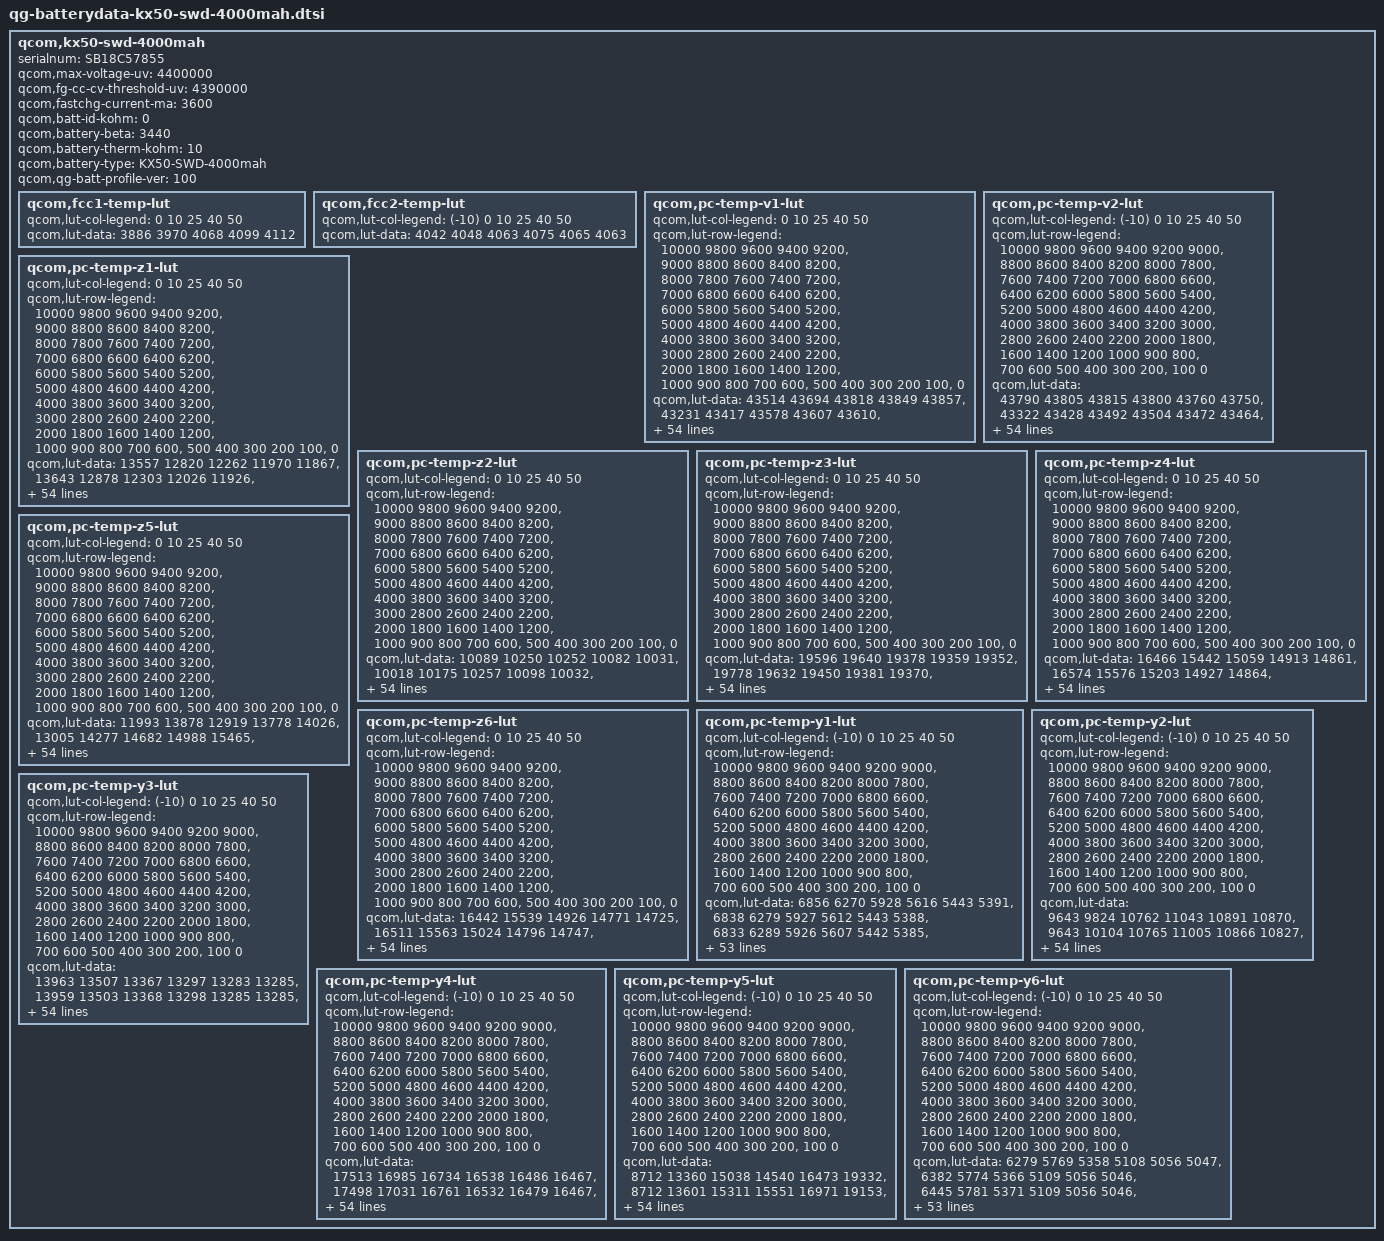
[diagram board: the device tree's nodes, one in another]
qcom,kx50-swd-4000mah {
    /* 4190768_LENOVO_Sofia_SUNWODA_4000MAH_PMI632_averaged_MasterSlave_Sep5th2019 */
    serialnum = "SB18C57855";
    qcom,max-voltage-uv = <4400000>;
    qcom,fg-cc-cv-threshold-uv = <4390000>;
    qcom,fastchg-current-ma = <3600>;
    qcom,batt-id-kohm = <0>;
    qcom,battery-beta = <3440>;
    qcom,battery-therm-kohm = <10>;
    qcom,battery-type = "KX50-SWD-4000mah";
    qcom,qg-batt-profile-ver = <100>;

	qcom,fcc1-temp-lut {
		qcom,lut-col-legend = <0 10 25 40 50>;
		qcom,lut-data = <3886 3970 4068 4099 4112>;
	};

	qcom,fcc2-temp-lut {
		qcom,lut-col-legend = <(-10) 0 10 25 40 50>;
		qcom,lut-data = <4042 4048 4063 4075 4065 4063>;
	};

	qcom,pc-temp-v1-lut {
		qcom,lut-col-legend = <0 10 25 40 50>;
		qcom,lut-row-legend = <10000 9800 9600 9400 9200>,
			<9000 8800 8600 8400 8200>,
			<8000 7800 7600 7400 7200>,
			<7000 6800 6600 6400 6200>,
			<6000 5800 5600 5400 5200>,
			<5000 4800 4600 4400 4200>,
			<4000 3800 3600 3400 3200>,
			<3000 2800 2600 2400 2200>,
			<2000 1800 1600 1400 1200>,
			<1000 900 800 700 600>,
			<500 400 300 200 100>,
			<0>;
		qcom,lut-data = <43514 43694 43818 43849 43857>,
			<43231 43417 43578 43607 43610>,
			<42978 43154 43331 43366 43376>,
			<42744 42908 43082 43125 43138>,
			<42517 42674 42837 42887 42901>,
			<42295 42443 42596 42648 42664>,
			<42080 42217 42361 42410 42429>,
			<41869 41997 42129 42175 42194>,
			<41662 41780 41902 41944 41962>,
			<41469 41567 41675 41716 41733>,
			<41309 41371 41452 41486 41505>,
			<41146 41207 41249 41265 41282>,
			<40917 41036 41080 41061 41063>,
			<40585 40790 40900 40865 40850>,
			<40279 40469 40639 40643 40642>,
			<40063 40202 40324 40392 40439>,
			<39887 40014 40100 40176 40246>,
			<39752 39862 39960 40023 40068>,
			<39644 39742 39833 39886 39899>,
			<39541 39640 39699 39736 39735>,
			<39430 39512 39554 39577 39578>,
			<39316 39329 39354 39388 39397>,
			<39193 39127 39064 39131 39151>,
			<39058 38930 38835 38895 38913>,
			<38920 38730 38718 38754 38769>,
			<38780 38596 38632 38651 38663>,
			<38638 38524 38550 38554 38561>,
			<38532 38470 38475 38463 38456>,
			<38461 38420 38406 38377 38359>,
			<38404 38377 38339 38293 38275>,
			<38363 38337 38277 38216 38200>,
			<38332 38297 38220 38152 38132>,
			<38305 38260 38168 38099 38071>,
			<38281 38225 38120 38048 38014>,
			<38260 38194 38079 37998 37960>,
			<38235 38161 38040 37948 37907>,
			<38210 38130 38002 37901 37852>,
			<38175 38094 37964 37857 37796>,
			<38121 38038 37912 37800 37727>,
			<38040 37948 37826 37714 37637>,
			<37942 37844 37722 37609 37531>,
			<37808 37730 37611 37497 37421>,
			<37673 37597 37483 37370 37297>,
			<37553 37430 37329 37216 37142>,
			<37406 37282 37185 37080 37009>,
			<37293 37189 37086 36993 36927>,
			<37255 37157 37060 36963 36901>,
			<37220 37138 37038 36945 36881>,
			<37187 37111 37022 36924 36858>,
			<37131 37059 36967 36860 36781>,
			<36896 36827 36714 36592 36488>,
			<36450 36383 36280 36153 36051>,
			<35876 35817 35714 35582 35477>,
			<35099 35037 34935 34801 34694>,
			<33874 33824 33726 33592 33478>,
			<30000 30000 30000 30000 30000>;
	};

	qcom,pc-temp-v2-lut {
		qcom,lut-col-legend = <(-10) 0 10 25 40 50>;
		qcom,lut-row-legend = <10000 9800 9600 9400 9200 9000>,
			<8800 8600 8400 8200 8000 7800>,
			<7600 7400 7200 7000 6800 6600>,
			<6400 6200 6000 5800 5600 5400>,
			<5200 5000 4800 4600 4400 4200>,
			<4000 3800 3600 3400 3200 3000>,
			<2800 2600 2400 2200 2000 1800>,
			<1600 1400 1200 1000 900 800>,
			<700 600 500 400 300 200>,
			<100 0>;
		qcom,lut-data = <43790 43805 43815 43800 43760 43750>,
			<43322 43428 43492 43504 43472 43464>,
			<42920 43086 43189 43224 43199 43193>,
			<42604 42785 42912 42963 42941 42937>,
			<42357 42517 42657 42718 42698 42696>,
			<42098 42269 42410 42479 42459 42458>,
			<41705 42047 42166 42240 42222 42221>,
			<41364 41832 41930 42005 41987 41987>,
			<41327 41569 41703 41776 41757 41756>,
			<41356 41256 41483 41551 41529 41528>,
			<41369 41080 41275 41329 41304 41303>,
			<41203 41038 41092 41111 41083 41082>,
			<40882 41003 40906 40897 40867 40866>,
			<40472 40785 40680 40694 40661 40658>,
			<39893 40207 40419 40496 40462 40455>,
			<39506 39798 40167 40283 40267 40260>,
			<39341 39631 39922 40034 40073 40072>,
			<39208 39495 39697 39809 39888 39892>,
			<39023 39320 39519 39662 39720 39724>,
			<38808 39126 39366 39544 39563 39563>,
			<38622 38938 39194 39382 39379 39378>,
			<38464 38757 38992 39143 39148 39149>,
			<38338 38583 38800 38912 38925 38928>,
			<38259 38406 38643 38739 38749 38751>,
			<38200 38236 38503 38592 38597 38598>,
			<38147 38133 38379 38467 38470 38470>,
			<38096 38077 38268 38360 38362 38361>,
			<38048 38032 38166 38264 38265 38262>,
			<38001 37987 38062 38174 38176 38171>,
			<37954 37946 37968 38092 38096 38088>,
			<37905 37905 37909 38018 38024 38015>,
			<37853 37866 37871 37950 37958 37949>,
			<37800 37825 37837 37888 37895 37885>,
			<37746 37780 37805 37829 37834 37822>,
			<37693 37730 37774 37775 37771 37755>,
			<37635 37677 37735 37721 37696 37669>,
			<37572 37618 37691 37668 37605 37559>,
			<37504 37555 37638 37607 37518 37455>,
			<37429 37486 37574 37536 37441 37372>,
			<37348 37411 37495 37458 37366 37295>,
			<37266 37332 37395 37377 37289 37218>,
			<37183 37248 37270 37285 37205 37136>,
			<37103 37160 37155 37169 37095 37029>,
			<37028 37067 37055 37038 36962 36897>,
			<36951 36946 36957 36920 36847 36784>,
			<36865 36812 36862 36863 36806 36751>,
			<36809 36755 36808 36845 36792 36739>,
			<36745 36704 36756 36823 36775 36720>,
			<36668 36654 36687 36783 36743 36687>,
			<36552 36572 36586 36690 36640 36564>,
			<36322 36393 36379 36410 36306 36198>,
			<35914 35998 35995 35907 35812 35695>,
			<35317 35391 35408 35271 35166 35039>,
			<34430 34543 34589 34395 34295 34141>,
			<33023 33155 33314 33121 32966 32787>,
			<28247 27971 28433 28065 28352 28266>;
	};

	qcom,pc-temp-z1-lut {
		qcom,lut-col-legend = <0 10 25 40 50>;
		qcom,lut-row-legend = <10000 9800 9600 9400 9200>,
			<9000 8800 8600 8400 8200>,
			<8000 7800 7600 7400 7200>,
			<7000 6800 6600 6400 6200>,
			<6000 5800 5600 5400 5200>,
			<5000 4800 4600 4400 4200>,
			<4000 3800 3600 3400 3200>,
			<3000 2800 2600 2400 2200>,
			<2000 1800 1600 1400 1200>,
			<1000 900 800 700 600>,
			<500 400 300 200 100>,
			<0>;
		qcom,lut-data = <13557 12820 12262 11970 11867>,
			<13643 12878 12303 12026 11926>,
			<13669 12908 12309 12028 11934>,
			<13684 12911 12309 12026 11937>,
			<13684 12903 12305 12024 11937>,
			<13661 12891 12298 12020 11937>,
			<13643 12868 12293 12017 11937>,
			<13644 12855 12287 12015 11938>,
			<13650 12858 12280 12014 11940>,
			<13647 12863 12279 12014 11942>,
			<13622 12862 12281 12015 11941>,
			<13585 12861 12281 12017 11941>,
			<13556 12859 12277 12017 11940>,
			<13521 12848 12270 12017 11940>,
			<13492 12816 12257 12012 11940>,
			<13470 12795 12241 12003 11940>,
			<13451 12789 12238 11998 11939>,
			<13453 12787 12243 12001 11939>,
			<13461 12793 12250 12005 11940>,
			<13469 12806 12256 12008 11941>,
			<13473 12819 12263 12010 11943>,
			<13472 12833 12269 12012 11944>,
			<13470 12845 12275 12013 11945>,
			<13466 12847 12278 12015 11945>,
			<13466 12845 12281 12017 11947>,
			<13472 12845 12284 12020 11950>,
			<13483 12854 12286 12024 11953>,
			<13495 12864 12288 12028 11957>,
			<13514 12862 12291 12032 11961>,
			<13536 12852 12297 12036 11965>,
			<13549 12849 12305 12040 11969>,
			<13557 12866 12308 12045 11973>,
			<13562 12890 12309 12049 11977>,
			<13556 12896 12310 12054 11981>,
			<13546 12897 12316 12059 11984>,
			<13548 12896 12323 12064 11987>,
			<13558 12897 12328 12069 11991>,
			<13569 12900 12332 12074 11994>,
			<13590 12907 12336 12078 11997>,
			<13618 12924 12342 12083 12000>,
			<13624 12933 12348 12087 12004>,
			<13604 12932 12357 12090 12008>,
			<13596 12933 12368 12094 12011>,
			<13615 12942 12370 12098 12014>,
			<13647 12958 12377 12103 12017>,
			<13648 12956 12388 12106 12018>,
			<13644 12969 12388 12107 12019>,
			<13611 12943 12391 12108 12020>,
			<13626 12974 12389 12112 12023>,
			<13650 12957 12399 12119 12026>,
			<13677 12967 12411 12122 12033>,
			<13723 12997 12419 12131 12041>,
			<13697 13033 12439 12145 12052>,
			<13739 13090 12451 12166 12068>,
			<13739 13090 12451 12166 12068>,
			<13739 13090 12451 12166 12068>;
	};

	qcom,pc-temp-z2-lut {
		qcom,lut-col-legend = <0 10 25 40 50>;
		qcom,lut-row-legend = <10000 9800 9600 9400 9200>,
			<9000 8800 8600 8400 8200>,
			<8000 7800 7600 7400 7200>,
			<7000 6800 6600 6400 6200>,
			<6000 5800 5600 5400 5200>,
			<5000 4800 4600 4400 4200>,
			<4000 3800 3600 3400 3200>,
			<3000 2800 2600 2400 2200>,
			<2000 1800 1600 1400 1200>,
			<1000 900 800 700 600>,
			<500 400 300 200 100>,
			<0>;
		qcom,lut-data = <10089 10250 10252 10082 10031>,
			<10018 10175 10257 10098 10032>,
			<10052 10174 10261 10179 10034>,
			<10065 10176 10257 10205 10095>,
			<10072 10154 10242 10201 10121>,
			<10083 10128 10214 10185 10071>,
			<10093 10106 10233 10169 10031>,
			<10093 10089 10432 10146 10020>,
			<10083 10076 10564 10102 9995>,
			<10075 10067 10415 10082 9971>,
			<10109 10064 10188 10089 9951>,
			<10176 10065 10149 10100 9938>,
			<10176 10068 10155 10088 9945>,
			<10067 10078 10165 10057 9959>,
			<9976 10099 10185 10066 9973>,
			<9968 10112 10211 10141 9985>,
			<9966 10115 10212 10181 9997>,
			<9968 10118 10179 10112 10006>,
			<9980 10128 10155 10033 10017>,
			<9994 10151 10178 10033 10032>,
			<10003 10179 10232 10066 10056>,
			<10010 10222 10288 10103 10080>,
			<10020 10257 10352 10151 10103>,
			<10037 10255 10380 10184 10123>,
			<10056 10241 10321 10174 10136>,
			<10070 10237 10239 10145 10146>,
			<10083 10244 10237 10141 10176>,
			<10094 10251 10276 10170 10328>,
			<10103 10253 10309 10206 10455>,
			<10110 10257 10329 10264 10385>,
			<10117 10262 10346 10346 10218>,
			<10123 10267 10355 10347 10108>,
			<10128 10273 10362 10249 10027>,
			<10132 10280 10365 10186 9988>,
			<10135 10289 10362 10185 10001>,
			<10141 10299 10359 10185 10027>,
			<10151 10308 10363 10184 10058>,
			<10164 10316 10371 10182 10104>,
			<10177 10328 10385 10185 10147>,
			<10193 10346 10419 10218 10185>,
			<10208 10357 10446 10267 10210>,
			<10227 10358 10445 10312 10206>,
			<10219 10360 10439 10347 10192>,
			<9980 10374 10436 10335 10198>,
			<10499 10475 10453 10309 10210>,
			<10708 10528 10475 10277 10184>,
			<10816 10524 10462 10257 10182>,
			<11020 10548 10458 10267 10195>,
			<11529 10556 10438 10288 10209>,
			<12272 10660 10467 10372 10267>,
			<11377 15617 10516 10307 10135>,
			<10316 10759 10445 10173 10023>,
			<10200 15315 10418 10118 9974>,
			<10044 10544 10355 10058 9925>,
			<10044 10544 10355 10058 9925>,
			<10044 10544 10355 10058 9925>;
	};

	qcom,pc-temp-z3-lut {
		qcom,lut-col-legend = <0 10 25 40 50>;
		qcom,lut-row-legend = <10000 9800 9600 9400 9200>,
			<9000 8800 8600 8400 8200>,
			<8000 7800 7600 7400 7200>,
			<7000 6800 6600 6400 6200>,
			<6000 5800 5600 5400 5200>,
			<5000 4800 4600 4400 4200>,
			<4000 3800 3600 3400 3200>,
			<3000 2800 2600 2400 2200>,
			<2000 1800 1600 1400 1200>,
			<1000 900 800 700 600>,
			<500 400 300 200 100>,
			<0>;
		qcom,lut-data = <19596 19640 19378 19359 19352>,
			<19778 19632 19450 19381 19370>,
			<19827 19643 19479 19415 19392>,
			<19847 19655 19494 19429 19408>,
			<19851 19661 19497 19433 19414>,
			<19844 19663 19498 19438 19417>,
			<19829 19661 19502 19441 19419>,
			<19813 19657 19516 19440 19420>,
			<19794 19654 19526 19436 19418>,
			<19782 19650 19516 19432 19415>,
			<19787 19645 19498 19427 19410>,
			<19805 19627 19484 19424 19405>,
			<19821 19608 19468 19418 19401>,
			<19840 19605 19455 19411 19399>,
			<19848 19609 19458 19410 19396>,
			<19834 19609 19469 19416 19394>,
			<19804 19598 19471 19419 19391>,
			<19778 19582 19454 19405 19385>,
			<19752 19568 19438 19386 19379>,
			<19734 19555 19432 19380 19373>,
			<19728 19551 19429 19378 19368>,
			<19725 19561 19432 19378 19366>,
			<19725 19571 19448 19382 19367>,
			<19732 19573 19458 19385 19367>,
			<19740 19574 19447 19378 19362>,
			<19743 19574 19430 19363 19348>,
			<19745 19570 19426 19359 19346>,
			<19746 19565 19425 19367 19387>,
			<19742 19562 19425 19379 19423>,
			<19735 19558 19431 19398 19422>,
			<19729 19556 19441 19421 19416>,
			<19721 19556 19448 19424 19410>,
			<19712 19555 19455 19416 19402>,
			<19704 19555 19457 19408 19394>,
			<19696 19554 19454 19402 19384>,
			<19688 19552 19450 19396 19374>,
			<19679 19548 19444 19389 19369>,
			<19671 19542 19436 19381 19366>,
			<19663 19537 19430 19376 19363>,
			<19656 19532 19428 19373 19361>,
			<19649 19527 19425 19371 19359>,
			<19644 19521 19423 19373 19360>,
			<19612 19514 19420 19376 19362>,
			<19308 19508 19414 19376 19368>,
			<19260 19485 19403 19371 19367>,
			<19259 19458 19396 19357 19355>,
			<19259 19456 19390 19357 19345>,
			<19259 19438 19389 19349 19340>,
			<19258 19436 19376 19344 19334>,
			<19257 19432 19368 19339 19336>,
			<19259 19346 19371 19351 19366>,
			<19261 19414 19387 19368 19366>,
			<19261 19341 19365 19371 19367>,
			<19262 19358 19363 19369 19368>,
			<19262 19358 19363 19369 19368>,
			<19262 19358 19363 19369 19368>;
	};

	qcom,pc-temp-z4-lut {
		qcom,lut-col-legend = <0 10 25 40 50>;
		qcom,lut-row-legend = <10000 9800 9600 9400 9200>,
			<9000 8800 8600 8400 8200>,
			<8000 7800 7600 7400 7200>,
			<7000 6800 6600 6400 6200>,
			<6000 5800 5600 5400 5200>,
			<5000 4800 4600 4400 4200>,
			<4000 3800 3600 3400 3200>,
			<3000 2800 2600 2400 2200>,
			<2000 1800 1600 1400 1200>,
			<1000 900 800 700 600>,
			<500 400 300 200 100>,
			<0>;
		qcom,lut-data = <16466 15442 15059 14913 14861>,
			<16574 15576 15203 14927 14864>,
			<16401 15580 15158 14953 14892>,
			<16088 15451 15063 14914 14872>,
			<15844 15277 14996 14876 14847>,
			<15675 15156 14942 14843 14824>,
			<15538 15070 14887 14815 14801>,
			<15433 15002 14823 14791 14780>,
			<15353 14951 14784 14772 14760>,
			<15272 14911 14777 14757 14746>,
			<15156 14875 14777 14744 14737>,
			<15036 14834 14769 14734 14730>,
			<14989 14804 14752 14725 14723>,
			<14978 14799 14741 14717 14716>,
			<14974 14804 14747 14717 14711>,
			<14961 14807 14762 14725 14706>,
			<14935 14798 14765 14729 14702>,
			<14904 14782 14738 14713 14695>,
			<14868 14760 14713 14694 14689>,
			<14835 14734 14707 14690 14688>,
			<14810 14726 14705 14689 14688>,
			<14790 14747 14721 14696 14692>,
			<14784 14782 14811 14768 14757>,
			<14786 14829 14873 14841 14831>,
			<14790 14892 14880 14851 14839>,
			<14807 14918 14883 14855 14840>,
			<14844 14906 14880 14853 14835>,
			<14862 14887 14863 14830 14779>,
			<14862 14869 14842 14801 14724>,
			<14859 14851 14821 14767 14712>,
			<14853 14833 14799 14733 14706>,
			<14840 14818 14779 14718 14701>,
			<14826 14804 14762 14711 14696>,
			<14813 14792 14752 14708 14694>,
			<14801 14782 14746 14708 14694>,
			<14789 14773 14743 14709 14695>,
			<14777 14764 14742 14709 14696>,
			<14767 14758 14740 14711 14697>,
			<14758 14757 14740 14713 14699>,
			<14751 14758 14746 14723 14711>,
			<14747 14759 14751 14732 14724>,
			<14743 14749 14745 14727 14720>,
			<14762 14736 14733 14715 14710>,
			<15050 14728 14728 14715 14709>,
			<15017 14703 14712 14709 14703>,
			<14982 14685 14685 14686 14680>,
			<14975 14678 14677 14678 14678>,
			<14968 14681 14663 14667 14665>,
			<14961 14673 14659 14648 14643>,
			<14950 14669 14660 14647 14634>,
			<14956 14775 14684 14674 14656>,
			<14975 14714 14678 14668 14667>,
			<14987 14797 14704 14669 14670>,
			<15003 14791 14708 14673 14671>,
			<15003 14791 14708 14673 14671>,
			<15003 14791 14708 14673 14671>;
	};

	qcom,pc-temp-z5-lut {
		qcom,lut-col-legend = <0 10 25 40 50>;
		qcom,lut-row-legend = <10000 9800 9600 9400 9200>,
			<9000 8800 8600 8400 8200>,
			<8000 7800 7600 7400 7200>,
			<7000 6800 6600 6400 6200>,
			<6000 5800 5600 5400 5200>,
			<5000 4800 4600 4400 4200>,
			<4000 3800 3600 3400 3200>,
			<3000 2800 2600 2400 2200>,
			<2000 1800 1600 1400 1200>,
			<1000 900 800 700 600>,
			<500 400 300 200 100>,
			<0>;
		qcom,lut-data = <11993 13878 12919 13778 14026>,
			<13005 14277 14682 14988 15465>,
			<13492 14741 15293 16581 16712>,
			<13804 15307 16013 17467 18067>,
			<14090 15923 16516 17906 18896>,
			<14364 16497 16865 18608 19495>,
			<14608 17094 17628 19338 20060>,
			<14815 17753 19726 19629 20662>,
			<14994 18654 21233 19796 21366>,
			<15232 19782 21006 20025 21835>,
			<15788 20486 20483 20715 22023>,
			<16778 20689 20499 21448 22182>,
			<18310 20959 20129 21579 22611>,
			<20595 22506 19653 21540 23422>,
			<21690 25884 21200 23156 24473>,
			<21194 27221 24442 27879 25894>,
			<20344 25490 25075 30039 26646>,
			<20124 23832 23111 26321 26547>,
			<20248 24073 21814 22185 26394>,
			<20494 25632 22952 22345 26495>,
			<21431 28517 25832 24345 27082>,
			<23652 37364 29915 25516 27369>,
			<26843 45677 36839 25814 26014>,
			<32751 45678 40623 25966 23587>,
			<38800 43089 34667 23611 20442>,
			<42905 40376 25263 18350 16545>,
			<46644 37012 22029 16692 15683>,
			<48116 33730 20659 16771 19972>,
			<46828 31952 20203 17011 24433>,
			<44671 30672 20924 20079 25848>,
			<42750 30214 22385 25234 26701>,
			<40702 30869 24548 26856 27369>,
			<38898 32096 27936 27244 27973>,
			<37460 33677 30595 27673 28292>,
			<36244 35906 32694 29003 27885>,
			<35380 37335 34071 30366 27079>,
			<34658 37991 33739 30066 26950>,
			<34272 38397 32329 28115 27177>,
			<34669 38368 31042 26188 27056>,
			<35524 37928 30014 24328 24972>,
			<35812 37227 28991 23037 22603>,
			<35734 35150 27916 23065 22043>,
			<34160 33431 26791 23305 21815>,
			<14051 33450 25330 23369 23530>,
			<11407 34145 25471 22939 24313>,
			<11437 30199 27162 20877 21355>,
			<11371 29900 25817 21275 18792>,
			<11353 23467 27185 20462 19019>,
			<11333 23637 23389 22529 21815>,
			<11328 24154 21713 21527 24303>,
			<11416 16686 19293 18617 25249>,
			<11372 17731 20216 19839 20826>,
			<11284 14413 15860 19056 19107>,
			<11182 13117 15086 17437 17355>,
			<11182 13117 15086 17437 17355>,
			<11182 13117 15086 17437 17355>;
	};

	qcom,pc-temp-z6-lut {
		qcom,lut-col-legend = <0 10 25 40 50>;
		qcom,lut-row-legend = <10000 9800 9600 9400 9200>,
			<9000 8800 8600 8400 8200>,
			<8000 7800 7600 7400 7200>,
			<7000 6800 6600 6400 6200>,
			<6000 5800 5600 5400 5200>,
			<5000 4800 4600 4400 4200>,
			<4000 3800 3600 3400 3200>,
			<3000 2800 2600 2400 2200>,
			<2000 1800 1600 1400 1200>,
			<1000 900 800 700 600>,
			<500 400 300 200 100>,
			<0>;
		qcom,lut-data = <16442 15539 14926 14771 14725>,
			<16511 15563 15024 14796 14747>,
			<16441 15552 15013 14821 14769>,
			<16268 15493 14982 14814 14770>,
			<16119 15400 14953 14805 14767>,
			<16010 15328 14926 14792 14759>,
			<15917 15275 14903 14780 14750>,
			<15840 15232 14884 14770 14742>,
			<15776 15199 14867 14759 14733>,
			<15718 15172 14855 14750 14726>,
			<15658 15145 14845 14742 14719>,
			<15603 15110 14834 14736 14713>,
			<15568 15080 14817 14728 14707>,
			<15545 15068 14804 14721 14703>,
			<15523 15062 14806 14720 14698>,
			<15494 15057 14814 14724 14695>,
			<15461 15047 14815 14726 14691>,
			<15429 15032 14795 14712 14685>,
			<15397 15017 14777 14694 14679>,
			<15375 15004 14774 14690 14675>,
			<15366 15000 14772 14688 14672>,
			<15360 15015 14781 14691 14672>,
			<15360 15038 14829 14725 14701>,
			<15367 15063 14861 14758 14733>,
			<15378 15091 14859 14758 14734>,
			<15392 15103 14854 14754 14729>,
			<15411 15098 14849 14750 14725>,
			<15420 15089 14842 14745 14723>,
			<15419 15082 14837 14741 14720>,
			<15417 15074 14833 14738 14717>,
			<15414 15067 14829 14736 14711>,
			<15407 15062 14826 14732 14706>,
			<15399 15058 14823 14726 14701>,
			<15393 15054 14820 14720 14695>,
			<15387 15052 14818 14718 14691>,
			<15382 15049 14815 14716 14686>,
			<15376 15046 14812 14713 14684>,
			<15373 15044 14809 14709 14682>,
			<15374 15044 14808 14707 14681>,
			<15375 15047 14811 14710 14686>,
			<15377 15049 14813 14714 14690>,
			<15381 15046 14811 14713 14689>,
			<15382 15042 14806 14711 14687>,
			<15371 15042 14803 14711 14689>,
			<15347 15031 14794 14707 14687>,
			<15338 15015 14781 14690 14671>,
			<15335 15011 14775 14687 14665>,
			<15333 15004 14769 14678 14656>,
			<15332 15002 14760 14667 14644>,
			<15335 15003 14760 14665 14642>,
			<15348 15012 14774 14685 14668>,
			<15367 15027 14784 14694 14677>,
			<15387 15038 14789 14699 14681>,
			<15420 15058 14797 14704 14686>,
			<15420 15058 14797 14704 14686>,
			<15420 15058 14797 14704 14686>;
	};

	qcom,pc-temp-y1-lut {
		qcom,lut-col-legend = <(-10) 0 10 25 40 50>;
		qcom,lut-row-legend = <10000 9800 9600 9400 9200 9000>,
			<8800 8600 8400 8200 8000 7800>,
			<7600 7400 7200 7000 6800 6600>,
			<6400 6200 6000 5800 5600 5400>,
			<5200 5000 4800 4600 4400 4200>,
			<4000 3800 3600 3400 3200 3000>,
			<2800 2600 2400 2200 2000 1800>,
			<1600 1400 1200 1000 900 800>,
			<700 600 500 400 300 200>,
			<100 0>;
		qcom,lut-data = <6856 6270 5928 5616 5443 5391>,
			<6838 6279 5927 5612 5443 5388>,
			<6833 6289 5926 5607 5442 5385>,
			<6835 6299 5925 5602 5440 5382>,
			<6839 6306 5924 5597 5439 5380>,
			<6841 6309 5923 5595 5436 5378>,
			<6847 6307 5923 5593 5434 5376>,
			<6855 6305 5923 5591 5431 5375>,
			<6856 6305 5922 5590 5429 5374>,
			<6856 6306 5921 5588 5427 5373>,
			<6856 6306 5920 5586 5426 5372>,
			<6855 6303 5917 5583 5424 5371>,
			<6854 6301 5915 5579 5423 5369>,
			<6856 6307 5916 5577 5421 5369>,
			<6862 6322 5920 5575 5416 5369>,
			<6866 6329 5924 5574 5415 5369>,
			<6861 6330 5928 5578 5420 5369>,
			<6853 6329 5931 5582 5425 5370>,
			<6850 6327 5932 5582 5424 5370>,
			<6846 6320 5933 5581 5421 5370>,
			<6844 6316 5933 5581 5420 5370>,
			<6843 6315 5929 5583 5421 5370>,
			<6842 6315 5926 5585 5422 5371>,
			<6844 6316 5927 5587 5424 5372>,
			<6851 6323 5931 5590 5426 5373>,
			<6853 6325 5934 5592 5428 5375>,
			<6844 6318 5938 5596 5431 5377>,
			<6833 6309 5940 5600 5433 5378>,
			<6836 6314 5939 5603 5436 5381>,
			<6855 6331 5936 5606 5439 5384>,
			<6863 6339 5936 5609 5442 5386>,
			<6856 6328 5946 5612 5446 5389>,
			<6848 6316 5954 5615 5449 5391>,
			<6850 6318 5950 5618 5452 5394>,
			<6858 6324 5941 5622 5455 5396>,
			<6861 6328 5939 5625 5457 5398>,
			<6847 6328 5945 5628 5459 5400>,
			<6831 6329 5949 5629 5461 5402>,
			<6830 6328 5949 5630 5463 5403>,
			<6829 6327 5949 5632 5464 5405>,
			<6830 6324 5951 5633 5466 5406>,
			<6843 6320 5957 5635 5468 5407>,
			<6855 6320 5958 5638 5470 5408>,
			<6862 6324 5953 5643 5473 5410>,
			<6863 6340 5956 5650 5478 5414>,
			<6879 6365 5974 5656 5483 5416>,
			<6869 6368 5971 5662 5484 5417>,
			<6858 6372 5966 5661 5482 5416>,
			<6861 6372 5980 5659 5482 5416>,
			<6893 6377 5984 5661 5480 5418>,
			<6941 6390 5990 5666 5486 5421>,
			<6937 6391 5990 5677 5494 5427>,
			<6941 6418 6007 5693 5505 5436>,
			<7000 6458 6041 5719 5522 5447>,
			<7000 6458 6041 5719 5522 5447>,
			<7000 6458 6041 5719 5522 5447>;
	};

	qcom,pc-temp-y2-lut {
		qcom,lut-col-legend = <(-10) 0 10 25 40 50>;
		qcom,lut-row-legend = <10000 9800 9600 9400 9200 9000>,
			<8800 8600 8400 8200 8000 7800>,
			<7600 7400 7200 7000 6800 6600>,
			<6400 6200 6000 5800 5600 5400>,
			<5200 5000 4800 4600 4400 4200>,
			<4000 3800 3600 3400 3200 3000>,
			<2800 2600 2400 2200 2000 1800>,
			<1600 1400 1200 1000 900 800>,
			<700 600 500 400 300 200>,
			<100 0>;
		qcom,lut-data = <9643 9824 10762 11043 10891 10870>,
			<9643 10104 10765 11005 10866 10827>,
			<9643 10291 10765 10969 10840 10785>,
			<9822 10402 10762 10935 10814 10747>,
			<10006 10456 10756 10905 10787 10713>,
			<10062 10468 10749 10880 10760 10687>,
			<9910 10387 10739 10857 10725 10668>,
			<9701 10278 10725 10838 10697 10652>,
			<9671 10344 10703 10827 10693 10637>,
			<9673 10654 10666 10820 10695 10623>,
			<9674 10804 10651 10815 10695 10613>,
			<9676 10589 10704 10803 10685 10608>,
			<9677 10338 10788 10792 10674 10605>,
			<9675 10387 10864 10796 10679 10602>,
			<9670 10613 10943 10816 10706 10602>,
			<9667 10739 10969 10846 10734 10602>,
			<9667 10782 10967 10916 10769 10605>,
			<9667 10811 10965 10998 10811 10612>,
			<9667 10827 10979 11067 10874 10669>,
			<9666 10839 11007 11127 10954 10800>,
			<9665 10839 11014 11139 10980 10848>,
			<9664 10778 10996 11108 10955 10834>,
			<9664 10659 10979 11082 10926 10820>,
			<9663 10358 10989 11087 10926 10828>,
			<9662 9867 11011 11101 10944 10847>,
			<9662 9700 11015 11115 10963 10869>,
			<9661 9695 10993 11135 10981 10898>,
			<9661 9691 10976 11157 11000 10924>,
			<9660 9686 10987 11179 11024 10940>,
			<9660 9681 11008 11199 11055 10954>,
			<9660 9677 11009 11214 11078 10981>,
			<9659 9673 10982 11227 11094 11027>,
			<9659 9669 10947 11231 11113 11048>,
			<9659 9667 10912 11231 11149 11047>,
			<9659 9665 10872 11230 11183 11045>,
			<9659 9663 10829 11220 11174 11032>,
			<9658 9662 10781 11184 11114 10999>,
			<9658 9660 10726 11146 11064 10977>,
			<9658 9659 10673 11114 11036 10961>,
			<9658 9659 10599 11085 11020 10941>,
			<9658 9658 10359 11063 11035 10916>,
			<9658 9658 9915 11041 11057 10894>,
			<9658 9658 9753 11007 11030 10901>,
			<9658 9657 9711 10950 10969 10899>,
			<9657 9657 9716 10929 10921 10799>,
			<9657 9658 9739 10901 10856 10733>,
			<9657 9658 9731 10880 10821 10684>,
			<9657 9657 9729 10873 10875 10668>,
			<9657 9657 9735 10888 10931 10756>,
			<9656 9657 9752 10890 10916 10735>,
			<9656 9657 9743 10841 10838 10671>,
			<9656 9656 9714 10750 10753 10594>,
			<9655 9656 9684 10675 10672 10513>,
			<9654 9655 9668 10610 10637 10429>,
			<9654 9655 9668 10610 10637 10429>,
			<9654 9655 9668 10610 10637 10429>;
	};

	qcom,pc-temp-y3-lut {
		qcom,lut-col-legend = <(-10) 0 10 25 40 50>;
		qcom,lut-row-legend = <10000 9800 9600 9400 9200 9000>,
			<8800 8600 8400 8200 8000 7800>,
			<7600 7400 7200 7000 6800 6600>,
			<6400 6200 6000 5800 5600 5400>,
			<5200 5000 4800 4600 4400 4200>,
			<4000 3800 3600 3400 3200 3000>,
			<2800 2600 2400 2200 2000 1800>,
			<1600 1400 1200 1000 900 800>,
			<700 600 500 400 300 200>,
			<100 0>;
		qcom,lut-data = <13963 13507 13367 13297 13283 13285>,
			<13959 13503 13368 13298 13285 13285>,
			<13939 13503 13371 13301 13286 13284>,
			<13906 13507 13373 13303 13287 13284>,
			<13863 13514 13376 13305 13288 13285>,
			<13813 13521 13378 13306 13289 13285>,
			<13736 13535 13381 13306 13290 13286>,
			<13665 13548 13384 13306 13290 13287>,
			<13650 13532 13387 13307 13290 13288>,
			<13645 13458 13389 13309 13291 13289>,
			<13644 13419 13391 13310 13292 13289>,
			<13656 13424 13390 13310 13292 13289>,
			<13672 13432 13389 13311 13293 13289>,
			<13654 13436 13383 13314 13294 13290>,
			<13589 13441 13371 13319 13297 13290>,
			<13559 13441 13364 13320 13298 13290>,
			<13572 13431 13361 13315 13299 13291>,
			<13588 13416 13359 13311 13300 13291>,
			<13589 13406 13355 13312 13300 13293>,
			<13586 13394 13351 13313 13300 13295>,
			<13583 13385 13347 13312 13299 13295>,
			<13579 13377 13341 13307 13294 13290>,
			<13575 13369 13336 13301 13290 13285>,
			<13585 13351 13333 13298 13287 13283>,
			<13619 13327 13330 13296 13285 13282>,
			<13652 13321 13328 13296 13284 13282>,
			<13683 13339 13325 13295 13283 13282>,
			<13716 13363 13323 13295 13283 13282>,
			<13754 13378 13319 13295 13283 13281>,
			<13797 13391 13316 13294 13283 13280>,
			<13841 13408 13315 13294 13283 13280>,
			<13888 13431 13319 13294 13283 13280>,
			<13937 13458 13323 13294 13283 13280>,
			<13987 13493 13327 13294 13283 13281>,
			<14038 13538 13331 13294 13284 13282>,
			<14087 13589 13335 13295 13284 13281>,
			<14133 13650 13339 13295 13283 13280>,
			<14178 13715 13343 13295 13282 13279>,
			<14221 13785 13348 13295 13282 13280>,
			<14261 13858 13354 13296 13283 13281>,
			<14299 13927 13360 13297 13284 13283>,
			<14333 13992 13369 13301 13287 13285>,
			<14373 14052 13387 13302 13287 13285>,
			<14425 14101 13415 13303 13284 13283>,
			<14470 14062 13428 13301 13284 13280>,
			<14475 13997 13424 13304 13289 13288>,
			<14537 14048 13439 13309 13292 13291>,
			<14608 14090 13456 13315 13296 13293>,
			<14686 14125 13469 13322 13301 13295>,
			<14771 14146 13479 13326 13299 13294>,
			<14861 14187 13486 13324 13295 13289>,
			<14994 14275 13506 13323 13297 13291>,
			<15200 14496 13561 13335 13302 13297>,
			<15707 14794 13718 13352 13312 13306>,
			<15707 14794 13718 13352 13312 13306>,
			<15707 14794 13718 13352 13312 13306>;
	};

	qcom,pc-temp-y4-lut {
		qcom,lut-col-legend = <(-10) 0 10 25 40 50>;
		qcom,lut-row-legend = <10000 9800 9600 9400 9200 9000>,
			<8800 8600 8400 8200 8000 7800>,
			<7600 7400 7200 7000 6800 6600>,
			<6400 6200 6000 5800 5600 5400>,
			<5200 5000 4800 4600 4400 4200>,
			<4000 3800 3600 3400 3200 3000>,
			<2800 2600 2400 2200 2000 1800>,
			<1600 1400 1200 1000 900 800>,
			<700 600 500 400 300 200>,
			<100 0>;
		qcom,lut-data = <17513 16985 16734 16538 16486 16467>,
			<17498 17031 16761 16532 16479 16467>,
			<17491 17086 16793 16528 16475 16467>,
			<17492 17140 16823 16525 16473 16467>,
			<17498 17185 16846 16524 16472 16467>,
			<17510 17211 16853 16524 16472 16467>,
			<17601 17221 16848 16525 16473 16466>,
			<17772 17229 16841 16528 16476 16466>,
			<17989 17260 16840 16531 16478 16466>,
			<18298 17353 16840 16535 16481 16469>,
			<18436 17478 16844 16540 16484 16471>,
			<18308 17709 16899 16546 16489 16475>,
			<18065 17918 16965 16553 16496 16480>,
			<17752 17769 16982 16565 16503 16485>,
			<17316 17213 16989 16584 16511 16491>,
			<17109 16961 16985 16602 16522 16497>,
			<17084 16996 16914 16616 16534 16506>,
			<17065 17038 16842 16632 16549 16516>,
			<17006 17027 16834 16663 16571 16534>,
			<16900 16972 16835 16699 16597 16556>,
			<16832 16911 16824 16699 16602 16562>,
			<16800 16839 16755 16624 16564 16538>,
			<16782 16772 16682 16551 16520 16508>,
			<16777 16728 16649 16522 16495 16488>,
			<16774 16695 16625 16504 16476 16472>,
			<16774 16682 16608 16501 16473 16470>,
			<16783 16677 16595 16503 16476 16470>,
			<16794 16676 16581 16505 16480 16471>,
			<16801 16681 16554 16510 16486 16476>,
			<16807 16698 16524 16517 16495 16485>,
			<16815 16716 16520 16523 16505 16495>,
			<16825 16740 16529 16529 16518 16507>,
			<16835 16763 16542 16531 16527 16518>,
			<16843 16777 16562 16529 16530 16526>,
			<16850 16788 16588 16526 16531 16531>,
			<16856 16797 16616 16525 16524 16525>,
			<16861 16805 16646 16522 16499 16496>,
			<16864 16812 16673 16521 16484 16479>,
			<16863 16821 16695 16520 16484 16479>,
			<16861 16836 16713 16521 16486 16481>,
			<16862 16856 16725 16528 16492 16488>,
			<16869 16885 16733 16542 16501 16499>,
			<16883 16922 16750 16547 16501 16498>,
			<16910 16968 16785 16546 16491 16482>,
			<16925 16968 16804 16528 16472 16459>,
			<16901 16922 16820 16540 16485 16480>,
			<16926 16972 16868 16562 16508 16510>,
			<16965 17035 16932 16594 16540 16548>,
			<17008 17107 17000 16641 16578 16588>,
			<17041 17164 17070 16677 16589 16577>,
			<17046 17181 17093 16650 16512 16492>,
			<17036 17126 17073 16611 16507 16491>,
			<17037 17113 17085 16650 16520 16497>,
			<17165 17113 17200 16714 16576 16537>,
			<17165 17113 17200 16714 16576 16537>,
			<17165 17113 17200 16714 16576 16537>;
	};

	qcom,pc-temp-y5-lut {
		qcom,lut-col-legend = <(-10) 0 10 25 40 50>;
		qcom,lut-row-legend = <10000 9800 9600 9400 9200 9000>,
			<8800 8600 8400 8200 8000 7800>,
			<7600 7400 7200 7000 6800 6600>,
			<6400 6200 6000 5800 5600 5400>,
			<5200 5000 4800 4600 4400 4200>,
			<4000 3800 3600 3400 3200 3000>,
			<2800 2600 2400 2200 2000 1800>,
			<1600 1400 1200 1000 900 800>,
			<700 600 500 400 300 200>,
			<100 0>;
		qcom,lut-data = <8712 13360 15038 14540 16473 19332>,
			<8712 13601 15311 15551 16971 19153>,
			<10634 13949 15583 16141 17236 18892>,
			<13552 14386 15825 16414 17327 18619>,
			<15117 14898 16004 16476 17299 18407>,
			<15545 15469 16089 16426 17207 18331>,
			<13797 16306 16069 15963 16799 18359>,
			<11397 17048 16038 15345 16204 18395>,
			<11426 16353 16180 15099 15826 18273>,
			<13275 13243 16587 14964 15548 17726>,
			<15511 11664 16729 14816 15244 17101>,
			<18582 13659 15128 14461 14779 16407>,
			<21216 16505 13304 14168 14415 15721>,
			<20030 17766 13790 14219 14480 15238>,
			<14945 18606 15807 14365 14747 14843>,
			<12579 18764 16916 14344 14816 14526>,
			<14144 18388 17146 14097 14432 14199>,
			<15939 18250 17361 13912 14096 14004>,
			<16032 18659 17920 14511 14204 14147>,
			<15654 19214 18819 16119 14607 14577>,
			<15047 19760 19423 17576 15334 15161>,
			<13440 20452 19760 19063 17307 16254>,
			<12026 20933 20032 19845 18752 17206>,
			<11948 18790 20280 19531 18687 17716>,
			<12069 13565 20496 18977 18417 18140>,
			<12156 11753 20723 18757 18063 18210>,
			<12140 12042 21037 18666 17235 17780>,
			<12131 12318 21225 18617 16468 17147>,
			<12255 12361 20094 18509 16115 16237>,
			<12451 12377 18144 18354 15885 15291>,
			<12542 12423 17737 18511 15913 15099>,
			<12585 12526 17932 19272 16120 15182>,
			<12640 12642 18029 19992 16436 15363>,
			<12788 12786 18009 20499 17641 16371>,
			<13013 12971 17947 20854 19266 17754>,
			<13167 13122 17757 20817 19508 18183>,
			<13278 13339 17306 20295 18946 18316>,
			<13333 13515 17028 19606 18305 18357>,
			<13280 13580 16998 18412 17723 18238>,
			<13144 13634 16972 17476 17326 18021>,
			<12975 13617 16430 17267 17615 18162>,
			<12723 13442 14741 17145 18149 18801>,
			<12547 13338 13791 16847 18106 19243>,
			<12494 13380 13446 16574 17362 19015>,
			<12579 13367 13559 16819 17065 16310>,
			<12917 13791 14308 16230 16290 16721>,
			<12914 13895 14259 16036 15800 15969>,
			<12930 13963 14402 15936 15896 15121>,
			<13152 14212 14599 16099 16145 14991>,
			<13676 14452 15083 16734 15804 14756>,
			<13640 14433 15493 17308 17023 15847>,
			<13103 13738 15237 17353 17679 15795>,
			<12748 12735 13927 17315 17920 17539>,
			<11973 12243 12592 18151 21159 21618>,
			<11973 12243 12592 18151 21159 21618>,
			<11973 12243 12592 18151 21159 21618>;
	};

	qcom,pc-temp-y6-lut {
		qcom,lut-col-legend = <(-10) 0 10 25 40 50>;
		qcom,lut-row-legend = <10000 9800 9600 9400 9200 9000>,
			<8800 8600 8400 8200 8000 7800>,
			<7600 7400 7200 7000 6800 6600>,
			<6400 6200 6000 5800 5600 5400>,
			<5200 5000 4800 4600 4400 4200>,
			<4000 3800 3600 3400 3200 3000>,
			<2800 2600 2400 2200 2000 1800>,
			<1600 1400 1200 1000 900 800>,
			<700 600 500 400 300 200>,
			<100 0>;
		qcom,lut-data = <6279 5769 5358 5108 5056 5047>,
			<6382 5774 5366 5109 5056 5046>,
			<6445 5781 5371 5109 5056 5046>,
			<6476 5788 5374 5109 5056 5046>,
			<6487 5794 5375 5109 5056 5046>,
			<6488 5798 5375 5109 5057 5046>,
			<6436 5799 5372 5109 5057 5047>,
			<6365 5801 5366 5109 5058 5048>,
			<6375 5795 5363 5109 5059 5048>,
			<6458 5774 5361 5111 5060 5049>,
			<6501 5764 5361 5113 5062 5051>,
			<6474 5822 5373 5114 5063 5052>,
			<6418 5893 5386 5116 5065 5053>,
			<6323 5858 5386 5121 5068 5055>,
			<6160 5717 5380 5130 5072 5057>,
			<6090 5650 5371 5135 5076 5059>,
			<6092 5654 5349 5137 5081 5062>,
			<6095 5659 5329 5139 5085 5065>,
			<6086 5654 5325 5146 5092 5071>,
			<6060 5636 5322 5157 5098 5079>,
			<6046 5618 5316 5157 5099 5080>,
			<6042 5602 5293 5132 5085 5069>,
			<6040 5585 5270 5107 5068 5056>,
			<6049 5567 5260 5097 5059 5049>,
			<6076 5550 5254 5091 5052 5044>,
			<6104 5547 5250 5090 5051 5043>,
			<6132 5567 5247 5091 5052 5043>,
			<6162 5596 5245 5092 5053 5044>,
			<6195 5624 5239 5094 5054 5045>,
			<6231 5657 5233 5096 5057 5047>,
			<6268 5694 5233 5099 5060 5050>,
			<6306 5736 5243 5102 5064 5053>,
			<6345 5782 5257 5103 5067 5057>,
			<6385 5830 5273 5103 5069 5060>,
			<6426 5881 5294 5104 5070 5062>,
			<6465 5934 5316 5104 5068 5060>,
			<6501 5991 5341 5105 5060 5051>,
			<6536 6051 5369 5105 5056 5046>,
			<6568 6113 5401 5106 5056 5047>,
			<6598 6177 5434 5108 5057 5048>,
			<6628 6239 5465 5113 5061 5052>,
			<6660 6299 5496 5121 5065 5057>,
			<6698 6357 5537 5126 5066 5056>,
			<6750 6410 5592 5128 5062 5051>,
			<6794 6384 5604 5124 5056 5043>,
			<6804 6320 5596 5132 5065 5055>,
			<6859 6374 5625 5143 5074 5066>,
			<6925 6424 5664 5158 5086 5078>,
			<6999 6474 5697 5177 5100 5092>,
			<7079 6512 5730 5191 5102 5087>,
			<7159 6553 5744 5183 5078 5060>,
			<7269 6611 5764 5175 5078 5062>,
			<7443 6784 5844 5205 5087 5069>,
			<7914 7025 6050 5247 5114 5090>,
			<7914 7025 6050 5247 5114 5090>,
			<7914 7025 6050 5247 5114 5090>;
	};

};
